# STM32F215 register map
File version: 1.1
CPU: CM3 r1p1, little endian, no MPU, no FPU, 4 interrupt priority bits
Registers are 32-bit, read-write, reset 0x0 unless marked. A register's access mark holds for its fields unless they carry their own. Offsets are from the block's base; [hi:lo] are bit positions; {n}, {i} and the like mark numbered series.

## RNG — Random number generator
Base 0x50060800
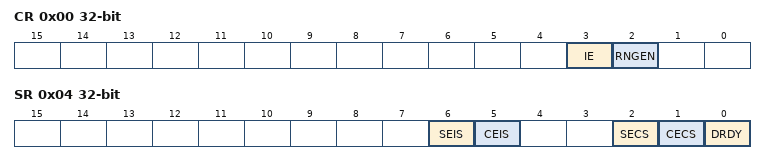
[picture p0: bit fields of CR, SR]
0x00 CR — control register
  [3] IE — Interrupt enable
    0=Disabled (RNG interrupt is disabled); 1=Enabled (RNG interrupt is enabled)
  [2] RNGEN — Random number generator enable
    0=Disabled (Random number generator is disabled); 1=Enabled (Random number generator is enabled)
0x04 SR access per field — status register
  [6] SEIS rw write-0-clears — Seed error interrupt status
    on write: 0=Clear flag | on read: 0=No faulty sequence detected; 1=Fault (At least one faulty sequence has been detected. See **SECS** bit description for details. An interrupt is pending if IE = 1 in the RNG_CR register.)
  [5] CEIS rw write-0-clears — Clock error interrupt status
    on write: 0=Clear flag | on read: 0=Correct (The RNG clock is correct); 1=Slow (The RNG has been detected too slow An interrupt is pending if IE = 1 in the RNG_CR register)
  [2] SECS ro — Seed error current status
    0=No faulty sequence has currently been detected. If the SEIS bit is set, this means that a faulty sequence was detected and the situation has been recovered.; 1=Fault (At least one faulty sequence has been detected - see ref manual for details)
  [1] CECS ro — Clock error current status
    0=Correct (The RNG clock is correct. If the CEIS bit is set, this means that a slow clock was detected and the situation has been recovered.); 1=Slow (The RNG clock is too slow)
  [0] DRDY ro — Data ready
    0=Invalid (The RNG_DR register is not yet valid, no random data is available); 1=Valid (The RNG_DR register contains valid random data. Once the RNG_DR register has been read, this bit returns to 0 until a new random value is generated.)
0x08 DR ro — data register
  [31:0] RNDATA — Random data

## CRC — cyclic redundancy check calculation unit
Base 0x40023000
0x00 DR reset 0xFFFFFFFF — Data register
  [31:0] DR — Data register bits
0x04 IDR — Independent data register
  [7:0] IDR — General-purpose 8-bit data register bits
0x08 CR wo — Control register
  [0] RESET — reset bit
    1=Resets the CRC calculation unit and sets the data register to 0xFFFF FFFF

## DBGMCU — Debug support
Base 0xE0042000
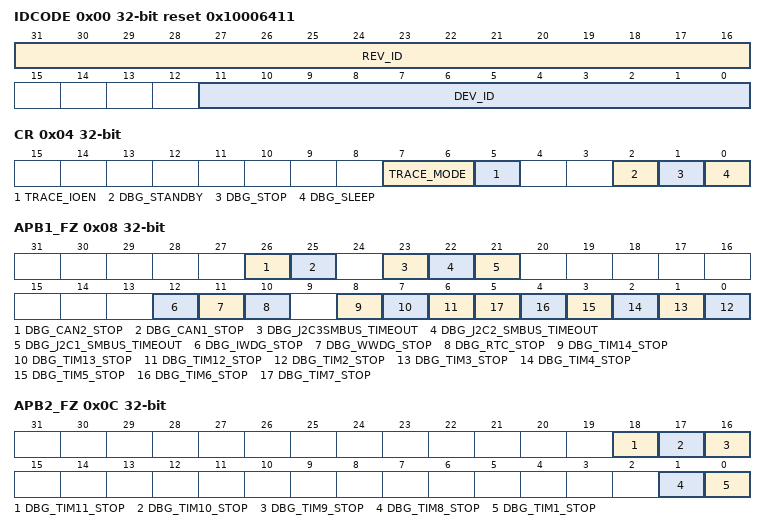
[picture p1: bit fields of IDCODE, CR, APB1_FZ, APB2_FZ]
0x00 IDCODE ro reset 0x10006411
  [31:16] REV_ID, [11:0] DEV_ID
0x04 CR — Control Register
  [7:6] TRACE_MODE, [5] TRACE_IOEN, [2] DBG_STANDBY, [1] DBG_STOP, [0] DBG_SLEEP
0x08 APB1_FZ — Debug MCU APB1 Freeze registe
  [26] DBG_CAN2_STOP
  [25] DBG_CAN1_STOP
  [23] DBG_J2C3SMBUS_TIMEOUT
  [22] DBG_J2C2_SMBUS_TIMEOUT
  [21] DBG_J2C1_SMBUS_TIMEOUT
  [12] DBG_IWDG_STOP — DBG_IWDEG_STOP
  [11] DBG_WWDG_STOP
  [10] DBG_RTC_STOP
  [8] DBG_TIM14_STOP
  [7] DBG_TIM13_STOP
  [6] DBG_TIM12_STOP
  [n-2] DBG_TIM{n}_STOP (n=2..7)
0x0C APB2_FZ — Debug MCU APB2 Freeze registe
  [18] DBG_TIM11_STOP — TIM11 counter stopped when core is halted
  [17] DBG_TIM10_STOP — TIM10 counter stopped when core is halted
  [16] DBG_TIM9_STOP — TIM9 counter stopped when core is halted
  [1] DBG_TIM8_STOP — TIM8 counter stopped when core is halted
  [0] DBG_TIM1_STOP — TIM1 counter stopped when core is halted

## GPIOI — General-purpose I/Os
Base 0x40022000
Same registers: GPIOC 0x40020800, GPIOD 0x40020C00, GPIOE 0x40021000, GPIOF 0x40021400, GPIOG 0x40021800, GPIOH 0x40021C00
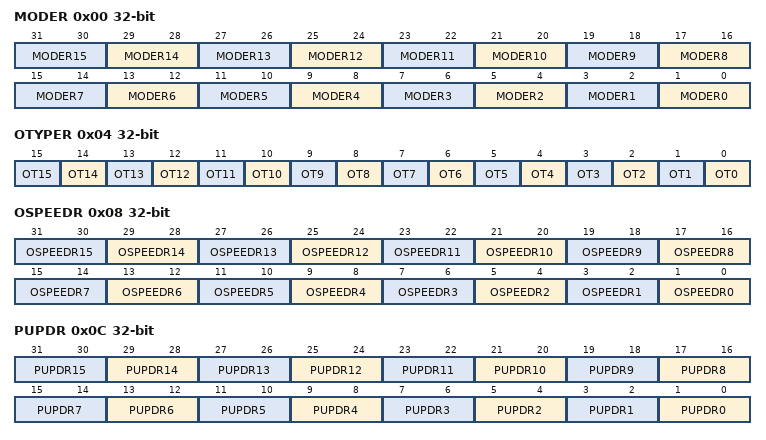
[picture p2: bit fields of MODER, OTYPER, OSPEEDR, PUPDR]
0x00 MODER — GPIO port mode register
  [2n+1:2n] MODER{n} (n=0..15) — Port x configuration pin {n}
    0=Input mode (reset state); 1=Output (General purpose output mode); 2=Alternate function mode; 3=Analog mode
0x04 OTYPER — GPIO port output type register
  [n] OT{n} (n=0..15) — Port x configuration pin {n}
    0=PushPull (Output push-pull (reset state)); 1=OpenDrain (Output open-drain)
0x08 OSPEEDR — GPIO port output speed register
  [2n+1:2n] OSPEEDR{n} (n=0..15) — Port x configuration pin {n}
    0=LowSpeed; 1=MediumSpeed; 2=HighSpeed; 3=VeryHighSpeed
0x0C PUPDR — GPIO port pull-up/pull-down register
  [2n+1:2n] PUPDR{n} (n=0..15) — Port x configuration pin {n}
    0=Floating (No pull-up, pull-down); 1=PullUp; 2=PullDown
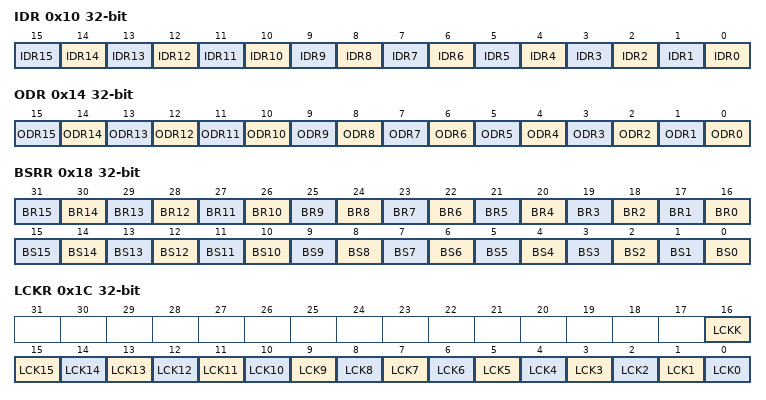
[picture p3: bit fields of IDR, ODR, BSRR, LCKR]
0x10 IDR ro — GPIO port input data register
  [n] IDR{n} (n=0..15) — Port input data pin {n}
    0=Low (Input is logic low); 1=High (Input is logic high)
0x14 ODR — GPIO port output data register
  [n] ODR{n} (n=0..15) — Port output data pin {n}
    0=Low (Set output to logic low); 1=High (Set output to logic high)
0x18 BSRR wo — GPIO port bit set/reset register
  [n+16] BR{n} (n=0..15) — Port x reset pin {n}
    1=Resets the corresponding ODRx bit
  [n] BS{n} (n=0..15) — Port x set pin {n}
    1=Set (Sets the corresponding ODRx bit)
0x1C LCKR — GPIO port configuration lock register
  [16] LCKK — Port x lock bit y (y= 0..15)
    0=NotActive (Port configuration lock key not active); 1=Active (Port configuration lock key active)
  [n] LCK{n} (n=0..15) — Port x lock pin {n}
    0=Unlocked (Port configuration not locked); 1=Locked (Port configuration locked)
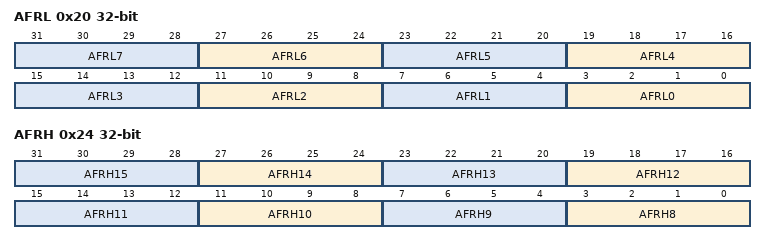
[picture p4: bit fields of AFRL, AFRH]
0x20 AFRL — GPIO alternate function low register
  [3:0] AFR{x} (x=L0,L1,L2,L3,L4,L5,L6,L7; step 4) — Alternate function selection for port x bit y (y = 0..7)
    {v}=AF{v} (v=0..15)
0x24 AFRH — GPIO alternate function high register
  [3:0] AFR{x} (x=H8,H9,H10,H11,H12,H13,H14,H15; step 4) — Alternate function selection for port x bit y (y = 8..15)
    {v}=AF{v} (v=0..15)

## GPIOB — General-purpose I/Os
Base 0x40020400
Registers as GPIOI; these are added or differ:
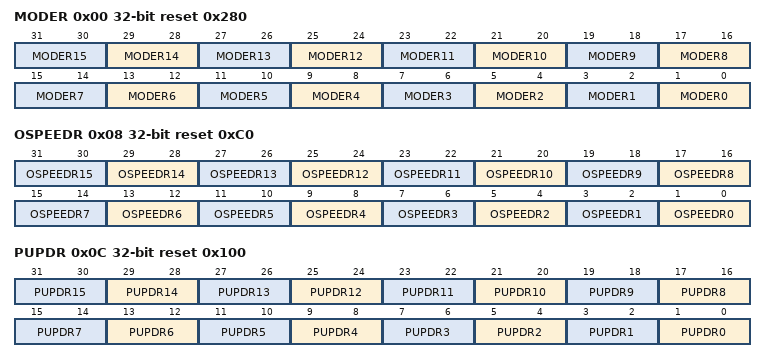
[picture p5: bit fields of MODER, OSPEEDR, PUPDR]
0x00 MODER reset 0x280 — GPIO port mode register
  [2n+1:2n] MODER{n} (n=0..15) — Port x configuration pin {n}
    0=Input mode (reset state); 1=Output (General purpose output mode); 2=Alternate function mode; 3=Analog mode
0x08 OSPEEDR reset 0xC0 — GPIO port output speed register
  [2n+1:2n] OSPEEDR{n} (n=0..15) — Port x configuration pin {n}
    0=LowSpeed; 1=MediumSpeed; 2=HighSpeed; 3=VeryHighSpeed
0x0C PUPDR reset 0x100 — GPIO port pull-up/pull-down register
  [2n+1:2n] PUPDR{n} (n=0..15) — Port x configuration pin {n}
    0=Floating (No pull-up, pull-down); 1=PullUp; 2=PullDown

## GPIOA — General-purpose I/Os
Base 0x40020000
Registers as GPIOI; these are added or differ:
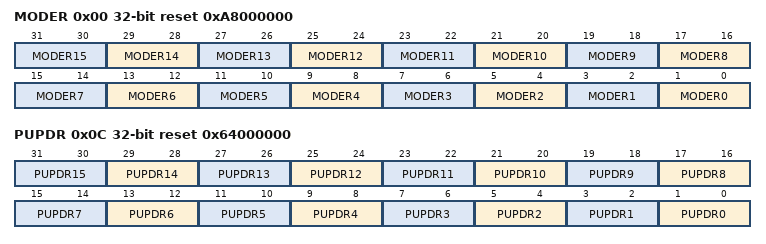
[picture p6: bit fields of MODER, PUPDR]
0x00 MODER reset 0xA8000000 — GPIO port mode register
  [2n+1:2n] MODER{n} (n=0..15) — Port x configuration pin {n}
    0=Input mode (reset state); 1=Output (General purpose output mode); 2=Alternate function mode; 3=Analog mode
0x0C PUPDR reset 0x64000000 — GPIO port pull-up/pull-down register
  [2n+1:2n] PUPDR{n} (n=0..15) — Port x configuration pin {n}
    0=Floating (No pull-up, pull-down); 1=PullUp; 2=PullDown
